AUTOSAR XML (schema 4-0-3)
package /ComponentTypes
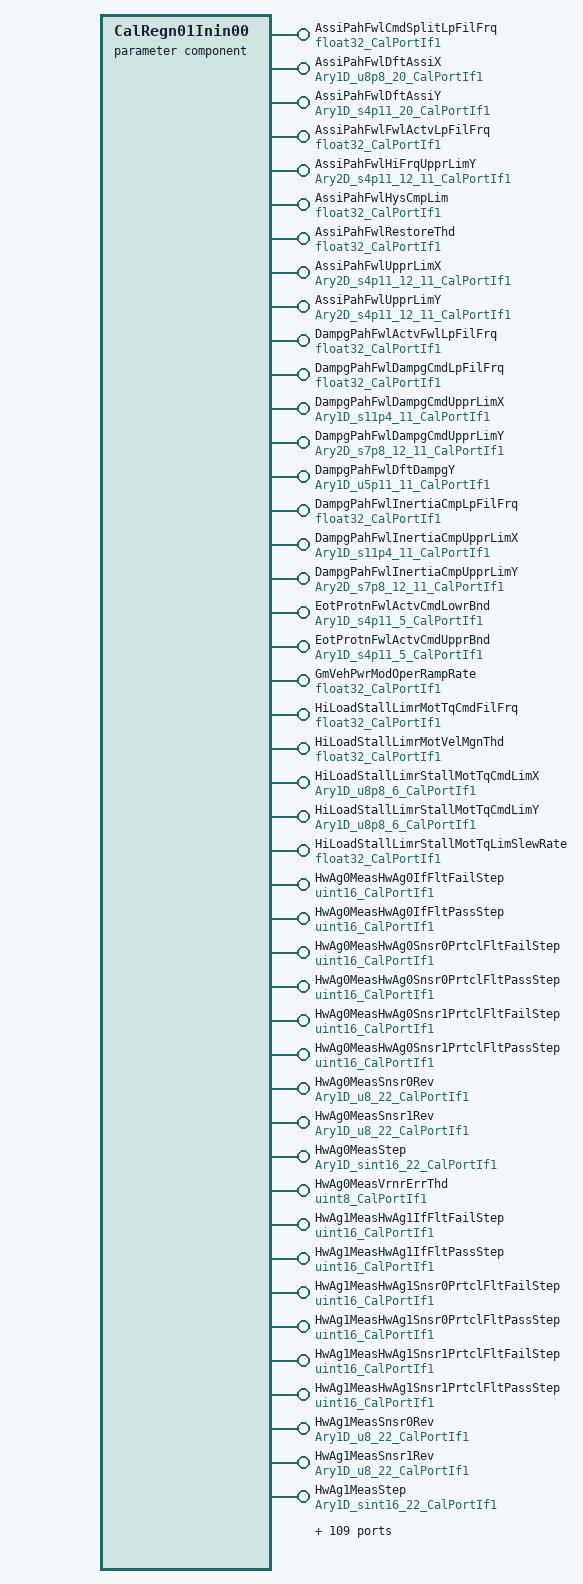
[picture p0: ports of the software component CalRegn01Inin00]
  parameter sw component type CalRegn01Inin00
    153 x provide port:
      AssiPahFwlCmdSplitLpFilFrq: parameter-provide-com-spec{init-value=50, parameter=Val}, provided-interface=float32_CalPortIf1
      AssiPahFwlDftAssiX: parameter-provide-com-spec{init-value=[0, 410, 460, 476, 503, 527, 558, 585, 619, 649, 677, 710, 738, 769, 797, 824, 1024, 1224, 1920, 2560], parameter=Ary1D}, provided-interface=Ary1D_u8p8_20_CalPortIf1
      AssiPahFwlDftAssiY: parameter-provide-com-spec{init-value=[0, 0, 0, 0, 6, 20, 43, 66, 96, 127, 156, 193, 229, 274, 319, 365, 786, 1358, 3635, 5120], parameter=Ary1D}, provided-interface=Ary1D_s4p11_20_CalPortIf1
      AssiPahFwlFwlActvLpFilFrq: parameter-provide-com-spec{init-value=0.1, parameter=Val}, provided-interface=float32_CalPortIf1
      AssiPahFwlHiFrqUpprLimY: parameter-provide-com-spec{init-value=12 x 11 x 18022, parameter=Ary2D}, provided-interface=Ary2D_s4p11_12_11_CalPortIf1
      AssiPahFwlHysCmpLim: parameter-provide-com-spec{init-value=0.15, parameter=Val}, provided-interface=float32_CalPortIf1
      AssiPahFwlRestoreThd: parameter-provide-com-spec{init-value=0.01, parameter=Val}, provided-interface=float32_CalPortIf1
      AssiPahFwlUpprLimX: parameter-provide-com-spec{init-value=[[-20480, -15360, -6144, -4096, -2048, 0, 2048, 4096, 6144, 15360, 20480], [-20480, -15360, -6144, -4096, -2048, 0, 2048, 4096, 6144, 15360, 20480], [-20480, -15360, -6144, -4096, -2048, 0, 2048, 4096, 6144, 15360, 20480], [-20480, -15360, -6144, -4096, -2048, 0, 2048, 4096, 6144, 15360, 20480], [-20480, -15360, -6144, -4096, -614, 0, 2048, 4096, 6144, 15360, 20480], [-20480, -15360, -6144, -4096, -614, 0, 2048, 4096, 6144, 15360, 20480], [-20480, -15360, -6144, -4096, -369, 0, 2048, 4096, 6144, 15360, 20480], [-20480, -15360, -6144, -4096, -369, 0, 2048, 4096, 6144, 15360, 20480], [-20480, -15360, -6144, -4096, -369, 0, 2048, 4096, 6144, 15360, 20480], [-20480, -15360, -6144, -4096, -369, 0, 2048, 4096, 6144, 15360, 20480], [-20480, -15360, -6144, -4096, -369, 0, 2048, 4096, 6144, 15360, 20480], [-20480, -15360, -6144, -4096, -369, 0, 2048, 4096, 6144, 15360, 20480]], parameter=Ary2D}, provided-interface=Ary2D_s4p11_12_11_CalPortIf1
      AssiPahFwlUpprLimY: parameter-provide-com-spec{init-value=12 x 11 x 18022, parameter=Ary2D}, provided-interface=Ary2D_s4p11_12_11_CalPortIf1
      DampgPahFwlActvFwlLpFilFrq: parameter-provide-com-spec{init-value=10, parameter=Val}, provided-interface=float32_CalPortIf1
      DampgPahFwlDampgCmdLpFilFrq: parameter-provide-com-spec{init-value=50, parameter=Val}, provided-interface=float32_CalPortIf1
      DampgPahFwlDampgCmdUpprLimX: parameter-provide-com-spec{init-value=[-9600, -1600, 0, 640, 1280, 1920, 3200, 4480, 5760, 7680, 9600], parameter=Ary1D}, provided-interface=Ary1D_s11p4_11_CalPortIf1
      DampgPahFwlDampgCmdUpprLimY: parameter-provide-com-spec{init-value=12 x 11 x 2253, parameter=Ary2D}, provided-interface=Ary2D_s7p8_12_11_CalPortIf1
      DampgPahFwlDftDampgY: parameter-provide-com-spec{init-value=[0, 101, 232, 393, 586, 807, 1061, 1349, 1663, 2005, 2376], parameter=Ary1D}, provided-interface=Ary1D_u5p11_11_CalPortIf1
      DampgPahFwlInertiaCmpLpFilFrq: parameter-provide-com-spec{init-value=50, parameter=Val}, provided-interface=float32_CalPortIf1
      DampgPahFwlInertiaCmpUpprLimX: parameter-provide-com-spec{init-value=[-9600, -1600, 0, 640, 1280, 1920, 3200, 4480, 5760, 7680, 9600], parameter=Ary1D}, provided-interface=Ary1D_s11p4_11_CalPortIf1
      DampgPahFwlInertiaCmpUpprLimY: parameter-provide-com-spec{init-value=12 x 11 x 2253, parameter=Ary2D}, provided-interface=Ary2D_s7p8_12_11_CalPortIf1
      EotProtnFwlActvCmdLowrBnd: parameter-provide-com-spec{init-value=5 x -512, parameter=Ary1D}, provided-interface=Ary1D_s4p11_5_CalPortIf1
      EotProtnFwlActvCmdUpprBnd: parameter-provide-com-spec{init-value=5 x 18022, parameter=Ary1D}, provided-interface=Ary1D_s4p11_5_CalPortIf1
      GmVehPwrModOperRampRate: parameter-provide-com-spec{init-value=0.5, parameter=Val}, provided-interface=float32_CalPortIf1
      HiLoadStallLimrMotTqCmdFilFrq: parameter-provide-com-spec{init-value=2, parameter=Val}, provided-interface=float32_CalPortIf1
      HiLoadStallLimrMotVelMgnThd: parameter-provide-com-spec{init-value=1.375, parameter=Val}, provided-interface=float32_CalPortIf1
      HiLoadStallLimrStallMotTqCmdLimX: parameter-provide-com-spec{init-value=[0, 563, 640, 717, 768, 768], parameter=Ary1D}, provided-interface=Ary1D_u8p8_6_CalPortIf1
      HiLoadStallLimrStallMotTqCmdLimY: parameter-provide-com-spec{init-value=[768, 768, 512, 256, 0, 0], parameter=Ary1D}, provided-interface=Ary1D_u8p8_6_CalPortIf1
      HiLoadStallLimrStallMotTqLimSlewRate: parameter-provide-com-spec{init-value=0.101563, parameter=Val}, provided-interface=float32_CalPortIf1
      HwAg0MeasHwAg0IfFltFailStep: parameter-provide-com-spec{init-value=2521, parameter=Val}, provided-interface=uint16_CalPortIf1
      HwAg0MeasHwAg0IfFltPassStep: parameter-provide-com-spec{init-value=1000, parameter=Val}, provided-interface=uint16_CalPortIf1
      HwAg0MeasHwAg0Snsr0PrtclFltFailStep: parameter-provide-com-spec{init-value=2521, parameter=Val}, provided-interface=uint16_CalPortIf1
      HwAg0MeasHwAg0Snsr0PrtclFltPassStep: parameter-provide-com-spec{init-value=1000, parameter=Val}, provided-interface=uint16_CalPortIf1
      HwAg0MeasHwAg0Snsr1PrtclFltFailStep: parameter-provide-com-spec{init-value=2521, parameter=Val}, provided-interface=uint16_CalPortIf1
      HwAg0MeasHwAg0Snsr1PrtclFltPassStep: parameter-provide-com-spec{init-value=1000, parameter=Val}, provided-interface=uint16_CalPortIf1
      HwAg0MeasSnsr0Rev: parameter-provide-com-spec{init-value=[0, 1, 1, 2, 2, 3, 3, 4, 4, 5, 5, 6, 6, 7, 7, 8, 8, 9, 9, 10, 10, 0], parameter=Ary1D}, provided-interface=Ary1D_u8_22_CalPortIf1
      HwAg0MeasSnsr1Rev: parameter-provide-com-spec{init-value=[0, 0, 1, 1, 2, 2, 3, 3, 4, 4, 5, 5, 6, 6, 7, 7, 8, 8, 9, 9, 0, 9], parameter=Ary1D}, provided-interface=Ary1D_u8_22_CalPortIf1
      HwAg0MeasStep: parameter-provide-com-spec{init-value=[0, -360, 36, -324, 72, -288, 108, -252, 144, -216, 180, -180, 216, -144, 252, -108, 288, -72, 324, -36, 360, -396], parameter=Ary1D}, provided-interface=Ary1D_sint16_22_CalPortIf1
      HwAg0MeasVrnrErrThd: parameter-provide-com-spec{init-value=8, parameter=Val}, provided-interface=uint8_CalPortIf1
      HwAg1MeasHwAg1IfFltFailStep: parameter-provide-com-spec{init-value=2521, parameter=Val}, provided-interface=uint16_CalPortIf1
      HwAg1MeasHwAg1IfFltPassStep: parameter-provide-com-spec{init-value=1000, parameter=Val}, provided-interface=uint16_CalPortIf1
      HwAg1MeasHwAg1Snsr0PrtclFltFailStep: parameter-provide-com-spec{init-value=2521, parameter=Val}, provided-interface=uint16_CalPortIf1
      HwAg1MeasHwAg1Snsr0PrtclFltPassStep: parameter-provide-com-spec{init-value=1000, parameter=Val}, provided-interface=uint16_CalPortIf1
      HwAg1MeasHwAg1Snsr1PrtclFltFailStep: parameter-provide-com-spec{init-value=2521, parameter=Val}, provided-interface=uint16_CalPortIf1
      HwAg1MeasHwAg1Snsr1PrtclFltPassStep: parameter-provide-com-spec{init-value=1000, parameter=Val}, provided-interface=uint16_CalPortIf1
      HwAg1MeasSnsr0Rev: parameter-provide-com-spec{init-value=[0, 1, 1, 2, 2, 3, 3, 4, 4, 5, 5, 6, 6, 7, 7, 8, 8, 9, 9, 10, 10, 0], parameter=Ary1D}, provided-interface=Ary1D_u8_22_CalPortIf1
      HwAg1MeasSnsr1Rev: parameter-provide-com-spec{init-value=[0, 0, 1, 1, 2, 2, 3, 3, 4, 4, 5, 5, 6, 6, 7, 7, 8, 8, 9, 9, 0, 9], parameter=Ary1D}, provided-interface=Ary1D_u8_22_CalPortIf1
      HwAg1MeasStep: parameter-provide-com-spec{init-value=[0, -360, 36, -324, 72, -288, 108, -252, 144, -216, 180, -180, 216, -144, 252, -108, 288, -72, 324, -36, 360, -396], parameter=Ary1D}, provided-interface=Ary1D_sint16_22_CalPortIf1
      HwAg1MeasVrnrErrThd: parameter-provide-com-spec{init-value=8, parameter=Val}, provided-interface=uint8_CalPortIf1
      HwAgSnsrlsVehDynVehSpdThd: parameter-provide-com-spec{init-value=65, parameter=Val}, provided-interface=float32_CalPortIf1
      HwAgSnsrlsVehDynYawRateThd: parameter-provide-com-spec{init-value=1, parameter=Val}, provided-interface=float32_CalPortIf1
      HwAgSnsrlsYawRateFilFrq: parameter-provide-com-spec{init-value=3, parameter=Val}, provided-interface=float32_CalPortIf1
      HwAgSysArbnTqSnsrVelFilFrq: parameter-provide-com-spec{init-value=20, parameter=Val}, provided-interface=float32_CalPortIf1
      HwTq0MeasHwTq0PrtclFltFailStep: parameter-provide-com-spec{init-value=2521, parameter=Val}, provided-interface=uint16_CalPortIf1
      HwTq0MeasHwTq0PrtclFltPassStep: parameter-provide-com-spec{init-value=1000, parameter=Val}, provided-interface=uint16_CalPortIf1
      HwTq1MeasHwTq1PrtclFltFailStep: parameter-provide-com-spec{init-value=2521, parameter=Val}, provided-interface=uint16_CalPortIf1
      HwTq1MeasHwTq1PrtclFltPassStep: parameter-provide-com-spec{init-value=1000, parameter=Val}, provided-interface=uint16_CalPortIf1
      LimrCdngGainDecSlew: parameter-provide-com-spec{init-value=500, parameter=Val}, provided-interface=float32_CalPortIf1
      LimrCdngGainIncSlewX: parameter-provide-com-spec{init-value=[1280, 2560], parameter=Ary1D}, provided-interface=Ary1D_u9p7_2_CalPortIf1
      LimrCdngGainIncSlewY: parameter-provide-com-spec{init-value=[64000, 64000], parameter=Ary1D}, provided-interface=Ary1D_u9p7_2_CalPortIf1
      LimrCdngTqDecSlew: parameter-provide-com-spec{init-value=4400, parameter=Val}, provided-interface=float32_CalPortIf1
      LimrCdngTqIncSlewX: parameter-provide-com-spec{init-value=[1280, 2560], parameter=Ary1D}, provided-interface=Ary1D_u9p7_2_CalPortIf1
      LimrCdngTqIncSlewY: parameter-provide-com-spec{init-value=[35200, 35200], parameter=Ary1D}, provided-interface=Ary1D_u13p3_2_CalPortIf1
      McuDiagc2MilliSecCntrCompThd: parameter-provide-com-spec{init-value=5, parameter=Val}, provided-interface=uint16_CalPortIf1
      McuDiagcFltFailStep: parameter-provide-com-spec{init-value=16385, parameter=Val}, provided-interface=uint16_CalPortIf1
      McuDiagcFltPassStep: parameter-provide-com-spec{init-value=160, parameter=Val}, provided-interface=uint16_CalPortIf1
      MotTqTranlDampgCmdLim: parameter-provide-com-spec{init-value=3, parameter=Val}, provided-interface=float32_CalPortIf1
      MotTqTranlDampgDampgCoeff: parameter-provide-com-spec{init-value=0.036, parameter=Val}, provided-interface=float32_CalPortIf1
      MotTqTranlDampgRampEnd: parameter-provide-com-spec{init-value=0, parameter=Val}, provided-interface=u2p14_CalPortIf1
      MotTqTranlDampgTmrPt1: parameter-provide-com-spec{init-value=100, parameter=Val}, provided-interface=float32_CalPortIf1
      MotTqTranlDampgTmrPt2: parameter-provide-com-spec{init-value=1000, parameter=Val}, provided-interface=float32_CalPortIf1
      MotTqTranlDampgVehSpdBlndX: parameter-provide-com-spec{init-value=[0, 1280, 2560, 12800], parameter=Ary1D}, provided-interface=Ary1D_u9p7_4_CalPortIf1
      MotTqTranlDampgVelThd: parameter-provide-com-spec{init-value=2.3, parameter=Val}, provided-interface=float32_CalPortIf1
      PwrDiscnctNtc0x042FailStep: parameter-provide-com-spec{init-value=1024, parameter=Val}, provided-interface=uint16_CalPortIf1
      PwrDiscnctNtc0x042PassStep: parameter-provide-com-spec{init-value=4096, parameter=Val}, provided-interface=uint16_CalPortIf1
      PwrDiscnctNtc0x04AFailStep: parameter-provide-com-spec{init-value=1024, parameter=Val}, provided-interface=uint16_CalPortIf1
      PwrDiscnctNtc0x04APassStep: parameter-provide-com-spec{init-value=4096, parameter=Val}, provided-interface=uint16_CalPortIf1
      RtnPahFwlUpprBndTblX: parameter-provide-com-spec{init-value=[-6400, -1600, 0, 800, 1600, 2400, 3200, 4000, 4800, 5600, 6400], parameter=Ary1D}, provided-interface=Ary1D_s11p4_11_CalPortIf1
      RtnPahFwlUpprBndTblY: parameter-provide-com-spec{init-value=8 x 11 x 18022, parameter=Ary2D}, provided-interface=Ary2D_s4p11_8_11_CalPortIf1
      RtnPahFwlVehSpd: parameter-provide-com-spec{init-value=[0, 384, 1280, 2560, 3840, 7680, 12800, 32640], parameter=Ary1D}, provided-interface=Ary1D_u9p7_8_CalPortIf1
      SnsrMeasStrtTrigDly: parameter-provide-com-spec{init-value=356, parameter=Val}, provided-interface=uint16_CalPortIf1
      StHlthSigNormnHiCtrlrT: parameter-provide-com-spec{init-value=140, parameter=Val}, provided-interface=float32_CalPortIf1
      StHlthSigNormnLoCtrlrT: parameter-provide-com-spec{init-value=-40, parameter=Val}, provided-interface=float32_CalPortIf1
      SysFricLrngAvrgFricFrq: parameter-provide-com-spec{init-value=0.1, parameter=Val}, provided-interface=float32_CalPortIf1
      SysFricLrngBasLineEolFric: parameter-provide-com-spec{init-value=0, parameter=Val}, provided-interface=float32_CalPortIf1
      SysFricLrngBasLineFric: parameter-provide-com-spec{init-value=[0, 0, 0, 0], parameter=Ary1D}, provided-interface=Ary1D_float32_4_CalPortIf1
      SysFricLrngBasLineHys: parameter-provide-com-spec{init-value=8 x [0, 0, 0, 0], parameter=Ary2D}, provided-interface=Ary2D_float32_8_4_CalPortIf1
      SysFricLrngBasLineRngCntr: parameter-provide-com-spec{init-value=8 x [0, 0, 0], parameter=Ary2D}, provided-interface=Ary2D_uint16_8_3_CalPortIf1
      SysFricLrngDataPrepLpFilFrq: parameter-provide-com-spec{init-value=30, parameter=Val}, provided-interface=float32_CalPortIf1
      SysFricLrngEolFricDifHiLim: parameter-provide-com-spec{init-value=1, parameter=Val}, provided-interface=float32_CalPortIf1
      SysFricLrngEolFricDifLoLim: parameter-provide-com-spec{init-value=-1, parameter=Val}, provided-interface=float32_CalPortIf1
      SysFricLrngEolFricDifScagFac: parameter-provide-com-spec{init-value=0.8, parameter=Val}, provided-interface=float32_CalPortIf1
      SysFricLrngFricChgWght: parameter-provide-com-spec{init-value=[1, 1, 1, 1], parameter=Ary1D}, provided-interface=Ary1D_float32_4_CalPortIf1
      SysFricLrngFricDiagcThd: parameter-provide-com-spec{init-value=15, parameter=Val}, provided-interface=float32_CalPortIf1
      SysFricLrngFricDiagcTiThd: parameter-provide-com-spec{init-value=50, parameter=Val}, provided-interface=float32_CalPortIf1
      SysFricLrngFricHysHwAgPt: parameter-provide-com-spec{init-value=[-15, -5, 5, 15], parameter=Ary1D}, provided-interface=Ary1D_float32_4_CalPortIf1
      SysFricLrngFricOffs: parameter-provide-com-spec{init-value=0, parameter=Val}, provided-interface=float32_CalPortIf1
      SysFricLrngFricOffsHiLim: parameter-provide-com-spec{init-value=1, parameter=Val}, provided-interface=float32_CalPortIf1
      SysFricLrngFricOffsLoLim: parameter-provide-com-spec{init-value=-1, parameter=Val}, provided-interface=float32_CalPortIf1
      SysFricLrngFricOffsLpFilFrq: parameter-provide-com-spec{init-value=4, parameter=Val}, provided-interface=float32_CalPortIf1
      SysFricLrngGain: parameter-provide-com-spec{init-value=0.2, parameter=Val}, provided-interface=float32_CalPortIf1
      SysFricLrngHwPosnAuthyThd: parameter-provide-com-spec{init-value=0.98, parameter=Val}, provided-interface=float32_CalPortIf1
      SysFricLrngHwVelConstrLim: parameter-provide-com-spec{init-value=360, parameter=Val}, provided-interface=float32_CalPortIf1
      SysFricLrngHwVelHiLim: parameter-provide-com-spec{init-value=180, parameter=Val}, provided-interface=float32_CalPortIf1
      SysFricLrngHwVelLoLim: parameter-provide-com-spec{init-value=10, parameter=Val}, provided-interface=float32_CalPortIf1
      SysFricLrngIgnCycFricChgLim: parameter-provide-com-spec{init-value=3, parameter=Val}, provided-interface=float32_CalPortIf1
      SysFricLrngIvsTrsmRatX: parameter-provide-com-spec{init-value=[0, 960, 1920, 2880, 3840, 5760, 8640, 11520, 14400, 17280], parameter=Ary1D}, provided-interface=Ary1D_u11p5_10_CalPortIf1
      SysFricLrngIvsTrsmRatY: parameter-provide-com-spec{init-value=10 x 24269, parameter=Ary1D}, provided-interface=Ary1D_u6p10_10_CalPortIf1
      SysFricLrngLatAHiLim: parameter-provide-com-spec{init-value=10, parameter=Val}, provided-interface=float32_CalPortIf1
      SysFricLrngLatALoLim: parameter-provide-com-spec{init-value=-10, parameter=Val}, provided-interface=float32_CalPortIf1
      SysFricLrngMaskVehSpd: parameter-provide-com-spec{init-value=[1, 1, 1, 1], parameter=Ary1D}, provided-interface=Ary1D_boolean_4_CalPortIf1
      SysFricLrngRngCntrThd: parameter-provide-com-spec{init-value=65534, parameter=Val}, provided-interface=uint16_CalPortIf1
      SysFricLrngThd: parameter-provide-com-spec{init-value=1, parameter=Val}, provided-interface=uint32_CalPortIf1
      SysFricLrngTHiLim: parameter-provide-com-spec{init-value=100, parameter=Val}, provided-interface=float32_CalPortIf1
      SysFricLrngTLoLim: parameter-provide-com-spec{init-value=0, parameter=Val}, provided-interface=float32_CalPortIf1
      SysFricLrngVehSpd: parameter-provide-com-spec{init-value=[[0, 5], [60, 80], [80, 100], [100, 120]], parameter=Ary2D}, provided-interface=Ary2D_float32_4_2_CalPortIf1
      SysGlbPrmMotPoleCnt: parameter-provide-com-spec{init-value=6, parameter=Val}, provided-interface=uint8_CalPortIf1
      SysGlbPrmTorsBarStfn: parameter-provide-com-spec{init-value=2.5, parameter=Val}, provided-interface=float32_CalPortIf1
      TEstimnAmbPwrMplr: parameter-provide-com-spec{init-value=0.01, parameter=Val}, provided-interface=float32_CalPortIf1
      TEstimnAmbTSca: parameter-provide-com-spec{init-value=0.9, parameter=Val}, provided-interface=float32_CalPortIf1
      TEstimnAssiMechAmbLpFilFrq: parameter-provide-com-spec{init-value=0.024, parameter=Val}, provided-interface=float32_CalPortIf1
      TEstimnAssiMechAmbMplr: parameter-provide-com-spec{init-value=0.01, parameter=Val}, provided-interface=float32_CalPortIf1
      TEstimnAssiMechCorrLim: parameter-provide-com-spec{init-value=60, parameter=Val}, provided-interface=float32_CalPortIf1
      TEstimnAssiMechDampgSca: parameter-provide-com-spec{init-value=0.0001, parameter=Val}, provided-interface=float32_CalPortIf1
      TEstimnAssiMechDftT: parameter-provide-com-spec{init-value=50, parameter=Val}, provided-interface=float32_CalPortIf1
      TEstimnAssiMechLLFilCoeffA1: parameter-provide-com-spec{init-value=0.99996858, parameter=Val}, provided-interface=float32_CalPortIf1
      TEstimnAssiMechLLFilCoeffB0: parameter-provide-com-spec{init-value=0.4761987, parameter=Val}, provided-interface=float32_CalPortIf1
      TEstimnAssiMechLLFilCoeffB1: parameter-provide-com-spec{init-value=-0.4761673, parameter=Val}, provided-interface=float32_CalPortIf1
      TEstimnAssiMechSlew: parameter-provide-com-spec{init-value=1, parameter=Val}, provided-interface=float32_CalPortIf1
      TEstimnCorrnTAssiMech: parameter-provide-com-spec{init-value=0, parameter=Val}, provided-interface=float32_CalPortIf1
      TEstimnCorrnTCu: parameter-provide-com-spec{init-value=0, parameter=Val}, provided-interface=float32_CalPortIf1
      TEstimnCorrnTMag: parameter-provide-com-spec{init-value=0, parameter=Val}, provided-interface=float32_CalPortIf1
      TEstimnCorrnTSi: parameter-provide-com-spec{init-value=0, parameter=Val}, provided-interface=float32_CalPortIf1
      TEstimnCuAmbLpFilFrq: parameter-provide-com-spec{init-value=0.024, parameter=Val}, provided-interface=float32_CalPortIf1
      TEstimnCuAmbMplr: parameter-provide-com-spec{init-value=0.75, parameter=Val}, provided-interface=float32_CalPortIf1
      TEstimnCuCorrnLim: parameter-provide-com-spec{init-value=80, parameter=Val}, provided-interface=float32_CalPortIf1
      TEstimnCuLLFilCoeffA1: parameter-provide-com-spec{init-value=0.999943, parameter=Val}, provided-interface=float32_CalPortIf1
      TEstimnCuLLFilCoeffB0: parameter-provide-com-spec{init-value=0.86667, parameter=Val}, provided-interface=float32_CalPortIf1
      TEstimnCuLLFilCoeffB1: parameter-provide-com-spec{init-value=-0.866613, parameter=Val}, provided-interface=float32_CalPortIf1
      TEstimnEngTSca: parameter-provide-com-spec{init-value=0.1, parameter=Val}, provided-interface=float32_CalPortIf1
      TEstimnMagAmbLpFilFrq: parameter-provide-com-spec{init-value=0.024, parameter=Val}, provided-interface=float32_CalPortIf1
      TEstimnMagCorrnLim: parameter-provide-com-spec{init-value=60, parameter=Val}, provided-interface=float32_CalPortIf1
      TEstimnMagLLFilCoeffA1: parameter-provide-com-spec{init-value=0.999962, parameter=Val}, provided-interface=float32_CalPortIf1
      TEstimnMagLLFilCoeffB0: parameter-provide-com-spec{init-value=0.571437, parameter=Val}, provided-interface=float32_CalPortIf1
      TEstimnMagLLFilCoeffB1: parameter-provide-com-spec{init-value=-0.571399, parameter=Val}, provided-interface=float32_CalPortIf1
      TEstimnSiAmbLpFilFrq: parameter-provide-com-spec{init-value=0.024, parameter=Val}, provided-interface=float32_CalPortIf1
      TEstimnSiAmbMplr: parameter-provide-com-spec{init-value=0, parameter=Val}, provided-interface=float32_CalPortIf1
      TEstimnSiCorrnLim: parameter-provide-com-spec{init-value=60, parameter=Val}, provided-interface=float32_CalPortIf1
      TEstimnSiLLFilCoeffA1: parameter-provide-com-spec{init-value=0.999889, parameter=Val}, provided-interface=float32_CalPortIf1
      TEstimnSiLLFilCoeffB0: parameter-provide-com-spec{init-value=1.68568, parameter=Val}, provided-interface=float32_CalPortIf1
      TEstimnSiLLFilCoeffB1: parameter-provide-com-spec{init-value=-1.68556, parameter=Val}, provided-interface=float32_CalPortIf1
      TEstimnWghtAvrgTDi: parameter-provide-com-spec{init-value=0, parameter=Logl}, provided-interface=boolean_CalPortIf1
      TunSelnAuthyVehSpdX: parameter-provide-com-spec{init-value=[0, 12800, 25600, 38400, 51200, 65408], parameter=Ary1D}, provided-interface=Ary1D_u9p7_6_CalPortIf1
      VehSigCdngLatASlewRate: parameter-provide-com-spec{init-value=10, parameter=Val}, provided-interface=float32_CalPortIf1
      VehSigCdngLtgASlewRate: parameter-provide-com-spec{init-value=50, parameter=Val}, provided-interface=float32_CalPortIf1
      VehSigCdngVehSpdSlewRate: parameter-provide-com-spec{init-value=50, parameter=Val}, provided-interface=float32_CalPortIf1
      WhlImbRejctnDcTrendFltRcvryThd: parameter-provide-com-spec{init-value=100, parameter=Val}, provided-interface=float32_CalPortIf1
